# YC3122 register map
Series: ARMCM0; File version: 1.0
CPU: CM0 r1p0, little endian, no MPU, no FPU, 8 interrupt priority bits
Registers are 32-bit, read-write, reset 0x0 unless marked. A register's access mark holds for its fields unless they carry their own. Offsets are from the block's base; [hi:lo] are bit positions.

## MHSPI
Base 0x000D8400
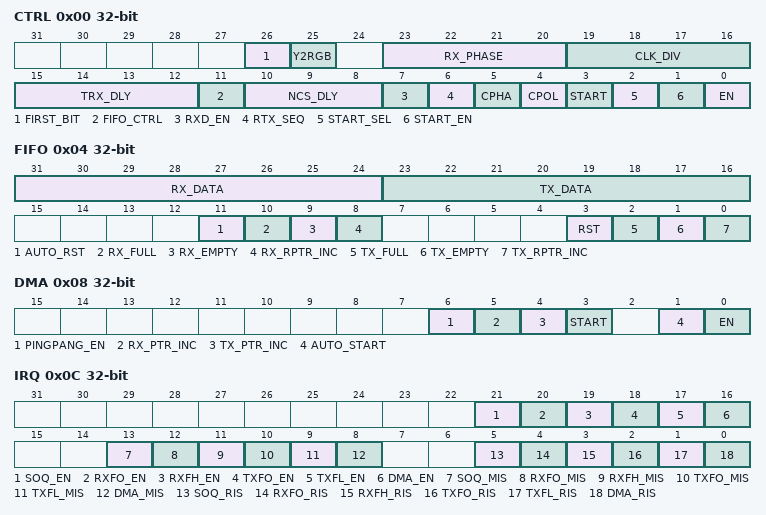
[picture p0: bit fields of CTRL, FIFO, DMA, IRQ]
0x00 CTRL
  [26] FIRST_BIT — 帧格式位 0：先发送MSB; 1：先发送LSB 注：y_to_rgb_mode为1时,先进行y转rgb操 作,再按配置比特顺序进行发送
  [25] Y2RGB — buff内容转RGB565控制位 0：无操作; 1：buffer内容为8-bit灰度，实际发送时会自动转 换为16-bit RGB565发送。
  [23:20] RX_PHASE — 控制接收相位调整值位,按bit采样位偏移N个cl k个 个数 0-7: 采样时间延后(rx_adj_clk + 1)* Hspi_clk不得大于clk_div。
  [19:16] CLK_DIV — HSPI预分频位 0-7：分频值为(clk_div + 1)*2。
  [15:12] TRX_DLY — 发送和接收保护间隔位 0-7：软件增加Hspi_clk*(trx_dly+1) *4个周期时长。
  [11] FIFO_CTRL — FIFO软件控制权限使能位 0: 软件无法操作FIFO,仅运行DMA自动操作 1: 软件可以操作FIFO,不使用DMA时,可以直接使用 FIFO进行收发
  [10:8] NCS_DLY — NCS提前拉低和滞后拉高的延时位 0-7：spi_clk*(ncs_dly+1)。
  [7] RXD_EN — 接收相位调整使能开关 0：失能相位调整; 1：使能相位调整。
  [6] RTX_SEQ — 收发序列控制位 0：收发同时进行，长度为tx_len; 1：先进行tx_len次发送, 再进行rx_len次接收 （rx_len为0时跳过接收）
  [5] CPHA — 时钟相位 0：空闲状态时，SCK保持低电平； 1：空闲状态时，SCK保持高电平；
  [4] CPOL — 时钟极性位 0：失能相位调整 1：使能相位调整
  [3] START — HSPI启动位，自动开启DMA_START. 0：无动作 1：硬件启动一次HSPI收发
  [2] START_SEL — DCMI多行中断选择 0: DCMI DMA0. 1: DCMI DMA1
  [1] START_EN — DCMI多行中断启动spi使能 0: 禁止硬件启动spi. 1: 允许硬件启动spi
  [0] EN — 接收相位调整使能开关 0：失能HSPI. 1：使能HSPI
0x04 FIFO
  [31:24] RX_DATA — 读取RX_FIFO数据 0-7：写寄存器时，直接将此字节写入Rx_FIFO， 读取此寄存器时，表示Rx_FIFO当前值;
  [23:16] TX_DATA — 读取Tx_FIFO数据 0-7：写寄存器时，直接将此字节写入Tx_FIFO， 读取此寄存器时，表示Tx_FIFO当前值;
  [11] AUTO_RST — fifo自动复位 0: do not effect. 1: 每次传输完成后,自动复位一下fifo
  [10] RX_FULL ro — RXFIFO状态位 0：非满; 1：满。
  [9] RX_EMPTY ro — RXFIFO状态位 0：非空; 1：空。
  [8] RX_RPTR_INC — 读取RXFIFO字节位，写1, RX_DATA读 地址加1. 0：无操作； 1：读取FIFO中一个字节
  [3] RST — 软件复位FIFO. 0: do not effect. 1: reset fifo
  [2] TX_FULL ro — TXFIFO状态位 0：非满; 1：满。
  [1] TX_EMPTY ro — TXFIFO状态位 0：非空; 1：空。
  [0] TX_RPTR_INC — 读取TXFIFO字节位，写1, TX_DATA读 地址加1. 0：无操作； 1：读取FIFO中一个字节；
0x08 DMA
  [6] PINGPANG_EN — SPI发送数据时,DMA从内存中乒乓buffer 取数 0: disable pingpang. 1: enable pingpang,tx_saddr~ tx_saddr+tx_len和tx_saddr+tx_ len ~ tx_saddr+tx_len*2
  [5] RX_PTR_INC — RXFIFO状态位 0：rx_addr自增; 1：rx_addr不自增。
  [4] TX_PTR_INC — TXFIFO状态位 0：tx_addr自增 1：tx_addr不自增。
  [3] START — 启动DMA传输位，同AUTO_START搭配使用 0：无操作； 1：启动一次dma传输任务
  [1] AUTO_START — DMA自动传输位 0：dma不会自动启动，必须手动通过dma_start_ man启动; 1：spi_start自动启动dma，无须手动启动dma 。
  [0] EN — DMA控制位 0：失能DMA; 1：使能DMA。
0x0C IRQ
  [21] SOQ_EN — 检测START信号丢失使能位 0: 失能； 1: 使能。
  [20] RXFO_EN — 接收FIFO溢出控制位 0: 失能接收FIFO未溢出; 1: 使能接收FIFO溢出;
  [19] RXFH_EN — 接收FIFO高水准线控制位 0: 失能高于低水准线; 1: 使能高于水准线。
  [18] TXFO_EN — 发送FIFO溢出控制位 0: 失能发送FIFO未溢出; 1: 使能发送FIFO溢出。
  [17] TXFL_EN — 发送FIFO低水准线控制位 0: 失能低于低水准线； 1: 使能低于低水准线。
  [16] DMA_EN — DMA发送完成控制位 0: 失能DMA发送; 1: 使能DMA发送。
  [13] SOQ_MIS — 丢失一次HSPI任务状态位 0: 未错过任务； 1: 出错，错过一次任务。
  [12] RXFO_MIS — 接收FIFO溢出状态位 0: 接收FIFO未溢出设定字节个数; 1: 接收FIFO溢出设定字节个数。
  [11] RXFH_MIS — 接收FIFO高水准线状态位 0: 不高于低水准线; 1: 高于水准线。
  [10] TXFO_MIS — 发送FIFO溢出状态位 0: 发送FIFO未溢出设定字节个数; 1: 发送FIFO溢出设定字节个数。
  [9] TXFL_MIS — 发送FIFO低水准线状态位 0: 不低于低水准线； 1: 低于低水准线。
  [8] DMA_MIS — DMA传输状态位 0: DMA发送未完成; 1: DMA发送完成。
  [5] SOQ_RIS — HSPI start信号来临时，上次传输还未完成 ， 此时会错过一个HSPI任务，出现错误。 0: 未错过任务； 1: 出错，错过一次任务
  [4] RXFO_RIS — 接收FIFO溢出标志位 0: 接收FIFO未溢出设定字节个数; 1: 接收FIFO溢出设定字节个数。
  [3] RXFH_RIS — 接收FIFO高水准线标志位 0: 不高于低水准线; 1: 高于水准线。
  [2] TXFO_RIS — 发送FIFO溢出标志位 0: 发送FIFO未溢出设定字节个数; 1: 发送FIFO溢出设定字节个数。
  [1] TXFL_RIS — 发送FIFO低水准线标志位 0: 不低于低水准线； 1: 低于低水准线；
  [0] DMA_RIS — DMA发送完成标志位 0: DMA发送未完成； 1: DMA完成一次传输发送；
0x10 DMA_TX_SADDR
  [19:0] VAL — 存放发送数据起始地址，必须四字节对齐。
0x14 DMA_RX_SADDR
  [19:0] VAL — 接收数据的起始地址，必须四字节对齐
0x18 DMA_TX_LEN
  [19:0] VAL — HSPI发送数据字节长度，配置为0时，表示仅接收
0x1C DMA_RX_LEN
  [19:0] VAL — HSPI接收数据字节长度，配置为0时，表示仅发送
0x20 DMA_TX_ADDR
  [19:0] VAL ro — 存放当前发送数据的地址。
0x24 DMA_RX_ADDR
  [19:0] VAL ro — 存放当前接收数据的地址。
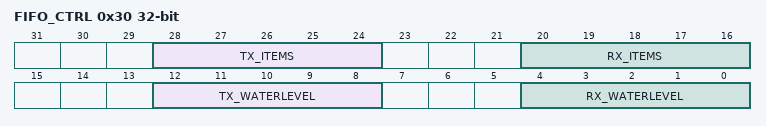
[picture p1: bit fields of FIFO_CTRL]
0x30 FIFO_CTRL
  [28:24] TX_ITEMS ro — 读取RX_FIFO的数据个数。
  [20:16] RX_ITEMS ro — 读取Tx_FIFO的数据个数。
  [12:8] TX_WATERLEVEL — 接收FIFO高水线， 接收FIFO数据大于等于此长度，并且水线值不为0时， 触发rx_fifo_hi中断。
  [4:0] RX_WATERLEVEL — 发送FIFO低水线， 发送FIFO数据小于等于此长度，并且水线值不为0时， 触发tx_fifo_lo中断。
